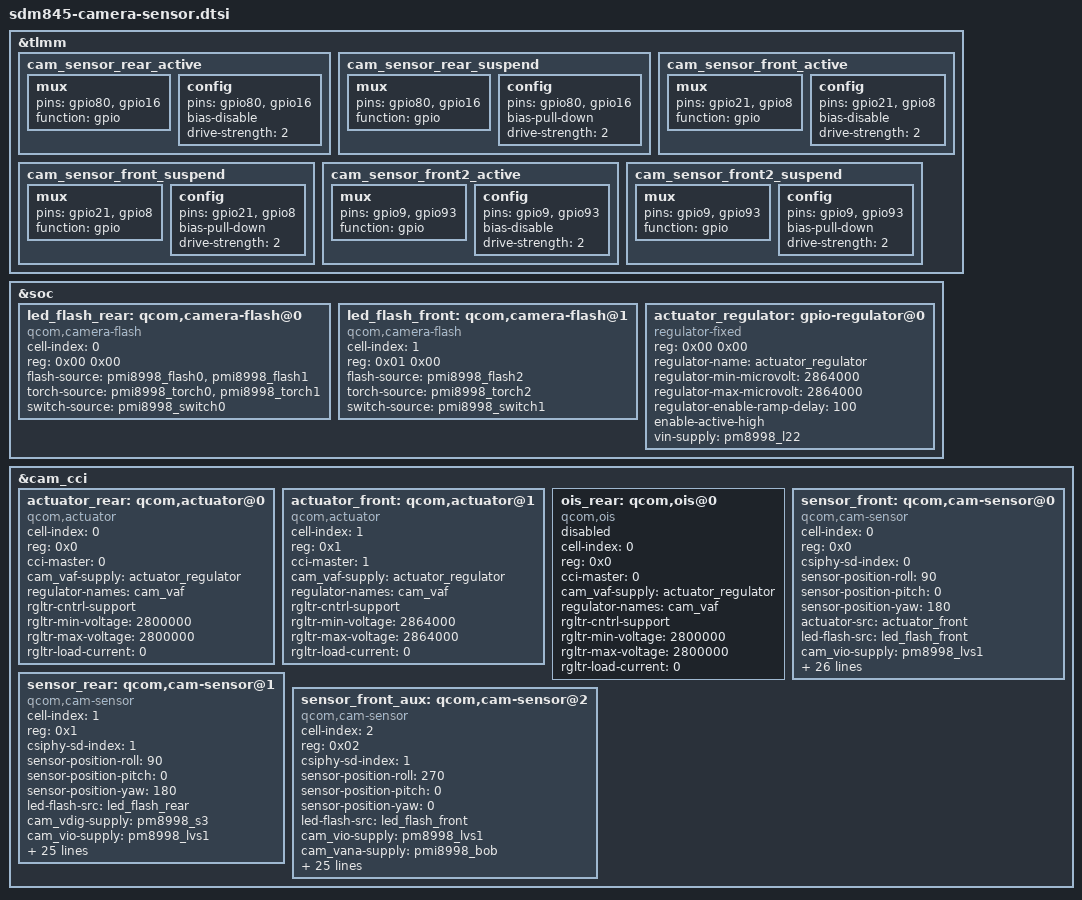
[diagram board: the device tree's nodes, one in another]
/*
 * Copyright (c) 2016-2017, The Linux Foundation. All rights reserved.
 *
 * This program is free software; you can redistribute it and/or modify
 * it under the terms of the GNU General Public License version 2 and
 * only version 2 as published by the Free Software Foundation.
 *
 * This program is distributed in the hope that it will be useful,
 * but WITHOUT ANY WARRANTY; without even the implied warranty of
 * MERCHANTABILITY or FITNESS FOR A PARTICULAR PURPOSE.  See the
 * GNU General Public License for more details.
 */

&tlmm {
	cam_sensor_rear_active: cam_sensor_rear_active {
		/* RESET, AVDD LDO */
		mux {
			pins = "gpio80","gpio16";
			function = "gpio";
		};

		config {
			pins = "gpio80","gpio16";
			bias-disable; /* No PULL */
			drive-strength = <2>; /* 2 MA */
		};
	};

	cam_sensor_rear_suspend: cam_sensor_rear_suspend {
		/* RESET, AVDD LDO */
		mux {
			pins = "gpio80","gpio16";
			function = "gpio";
		};

		config {
			pins = "gpio80","gpio16";
			bias-pull-down; /* PULL DOWN */
			drive-strength = <2>; /* 2 MA */
		};
	};

	cam_sensor_front_active: cam_sensor_front_active {
		/* RESET  AVDD_LDO*/
		mux {
			pins = "gpio21", "gpio8";
			function = "gpio";
		};

		config {
			pins = "gpio21", "gpio8";
			bias-disable; /* No PULL */
			drive-strength = <2>; /* 2 MA */
		};
	};

	cam_sensor_front_suspend: cam_sensor_front_suspend {
		/* RESET  AVDD_LDO*/
		mux {
			pins = "gpio21", "gpio8";
			function = "gpio";
		};

		config {
			pins = "gpio21", "gpio8";
			bias-pull-down; /* PULL DOWN */
			drive-strength = <2>; /* 2 MA */
		};
	};

	cam_sensor_front2_active: cam_sensor_front2_active {
		/* RESET  AVDD_LDO*/
		mux {
			pins = "gpio9", "gpio93";
			function = "gpio";
		};

		config {
			pins = "gpio9", "gpio93";
			bias-disable; /* No PULL */
			drive-strength = <2>; /* 2 MA */
		};
	};

	cam_sensor_front2_suspend: cam_sensor_front2_suspend {
		/* RESET  AVDD_LDO*/
		mux {
			pins = "gpio9", "gpio93";
			function = "gpio";
		};

		config {
			pins = "gpio9", "gpio93";
			bias-pull-down; /* PULL DOWN */
			drive-strength = <2>; /* 2 MA */
		};
	};
};

&soc {
	led_flash_rear: qcom,camera-flash@0 {
		cell-index = <0>;
		reg = <0x00 0x00>;
		compatible = "qcom,camera-flash";
		flash-source = <&pmi8998_flash0 &pmi8998_flash1>;
		torch-source = <&pmi8998_torch0 &pmi8998_torch1>;
		switch-source = <&pmi8998_switch0>;
		status = "ok";
	};

	led_flash_front: qcom,camera-flash@1 {
		cell-index = <1>;
		reg = <0x01 0x00>;
		compatible = "qcom,camera-flash";
		flash-source = <&pmi8998_flash2>;
		torch-source = <&pmi8998_torch2>;
		switch-source = <&pmi8998_switch1>;
		status = "ok";
	};

	actuator_regulator: gpio-regulator@0 {
		compatible = "regulator-fixed";
		reg = <0x00 0x00>;
		regulator-name = "actuator_regulator";
		regulator-min-microvolt = <2864000>;
		regulator-max-microvolt = <2864000>;
		regulator-enable-ramp-delay = <100>;
		enable-active-high;
		vin-supply = <&pm8998_l22>;
	};
};

&cam_cci {
	actuator_rear: qcom,actuator@0 {
		cell-index = <0>;
		reg = <0x0>;
		compatible = "qcom,actuator";
		cci-master = <0>;
		cam_vaf-supply = <&actuator_regulator>;
		regulator-names = "cam_vaf";
		rgltr-cntrl-support;
		rgltr-min-voltage = <2800000>;
		rgltr-max-voltage = <2800000>;
		rgltr-load-current = <0>;
	};

	actuator_front: qcom,actuator@1 {
		cell-index = <1>;
		reg = <0x1>;
		compatible = "qcom,actuator";
		cci-master = <1>;
		cam_vaf-supply = <&actuator_regulator>;
		regulator-names = "cam_vaf";
		rgltr-cntrl-support;
		rgltr-min-voltage = <2864000>;
		rgltr-max-voltage = <2864000>;
		rgltr-load-current = <0>;
	};

	ois_rear: qcom,ois@0 {
		cell-index = <0>;
		reg = <0x0>;
		compatible = "qcom,ois";
		cci-master = <0>;
		cam_vaf-supply = <&actuator_regulator>;
		regulator-names = "cam_vaf";
		rgltr-cntrl-support;
		rgltr-min-voltage = <2800000>;
		rgltr-max-voltage = <2800000>;
		rgltr-load-current = <0>;
		status = "disabled";
	};

	sensor_front: qcom,cam-sensor@0 {
		cell-index = <0>;
		compatible = "qcom,cam-sensor";
		reg = <0x0>;
		csiphy-sd-index = <0>;
		sensor-position-roll = <90>;
		sensor-position-pitch = <0>;
		sensor-position-yaw = <180>;
		actuator-src = <&actuator_front>;
		led-flash-src = <&led_flash_front>;
		cam_vio-supply = <&pm8998_lvs1>;
		cam_vana-supply = <&pmi8998_bob>;
		cam_vdig-supply = <&pm8998_s3>;
		cam_clk-supply = <&titan_top_gdsc>;
		regulator-names = "cam_vio", "cam_vana", "cam_vdig",
			"cam_clk";
		rgltr-cntrl-support;
		rgltr-min-voltage = <0 3312000 1352000 0>;
		rgltr-max-voltage = <0 3600000 1352000 0>;
		rgltr-load-current = <0 80000 105000 0>;
		gpio-no-mux = <0>;
		pinctrl-names = "cam_default", "cam_suspend";
		pinctrl-0 = <&cam_sensor_mclk1_active
				&cam_sensor_front_active>;
		pinctrl-1 = <&cam_sensor_mclk1_suspend
				&cam_sensor_front_suspend>;
		gpios = <&tlmm 14 0>,
			<&tlmm 21 0>,
			<&tlmm 8 0>;
		gpio-reset = <1>;
		gpio-vana = <2>;
		gpio-req-tbl-num = <0 1 2>;
		gpio-req-tbl-flags = <1 0 0>;
		gpio-req-tbl-label = "CAMIF_MCLK1",
					"CAM_RESET1",
					"CAM_VANA1";
		sensor-mode = <0>;
		cci-master = <1>;
		status = "ok";
		clocks = <&clock_camcc CAM_CC_MCLK1_CLK>;
		clock-names = "cam_clk";
		clock-cntl-level = "turbo";
		clock-rates = <24000000>;
	};

	sensor_rear: qcom,cam-sensor@1 {
		cell-index = <1>;
		compatible = "qcom,cam-sensor";
		reg = <0x1>;
		csiphy-sd-index = <1>;
		sensor-position-roll = <90>;
		sensor-position-pitch = <0>;
		sensor-position-yaw = <180>;
		led-flash-src = <&led_flash_rear>;
		cam_vdig-supply = <&pm8998_s3>;
		cam_vio-supply = <&pm8998_lvs1>;
		cam_vana-supply = <&pmi8998_bob>;
		cam_clk-supply = <&titan_top_gdsc>;
		regulator-names = "cam_vdig", "cam_vio", "cam_vana",
			"cam_clk";
		rgltr-cntrl-support;
		rgltr-min-voltage = <1352000 0 3312000 0>;
		rgltr-max-voltage = <1352000 0 3600000 0>;
		rgltr-load-current = <105000 0 80000 0>;
		gpio-no-mux = <0>;
		pinctrl-names = "cam_default", "cam_suspend";
		pinctrl-0 = <&cam_sensor_mclk0_active
				&cam_sensor_rear_active>;
		pinctrl-1 = <&cam_sensor_mclk0_suspend
				&cam_sensor_rear_suspend>;
		gpios = <&tlmm 13 0>,
			<&tlmm 80 0>,
			<&tlmm 16 0>;
		gpio-reset = <1>;
		gpio-vana = <2>;
		gpio-req-tbl-num = <0 1 2>;
		gpio-req-tbl-flags = <1 0 0>;
		gpio-req-tbl-label = "CAMIF_MCLK0",
					"CAM_RESET0",
					"CAM_VANA0";
		sensor-mode = <0>;
		cci-master = <0>;
		status = "ok";
		clocks = <&clock_camcc CAM_CC_MCLK0_CLK>;
		clock-names = "cam_clk";
		clock-cntl-level = "turbo";
		clock-rates = <24000000>;
	};

	sensor_front_aux: qcom,cam-sensor@2 {
		cell-index = <2>;
		compatible = "qcom,cam-sensor";
		reg = <0x02>;
		csiphy-sd-index = <1>;
		sensor-position-roll = <270>;
		sensor-position-pitch = <0>;
		sensor-position-yaw = <0>;
		//eeprom-src = <&eeprom_front>;
		led-flash-src = <&led_flash_front>;
		cam_vio-supply = <&pm8998_lvs1>;
		cam_vana-supply = <&pmi8998_bob>;
		cam_vdig-supply = <&pm8998_s3>;
		cam_clk-supply = <&titan_top_gdsc>;
		regulator-names = "cam_vio", "cam_vana", "cam_vdig",
			"cam_clk";
		rgltr-cntrl-support;
		rgltr-min-voltage = <0 3312000 1352000 0>;
		rgltr-max-voltage = <0 3600000 1352000 0>;
		rgltr-load-current = <0 80000 105000 0>;
		gpio-no-mux = <0>;
		pinctrl-names = "cam_default", "cam_suspend";
		pinctrl-0 = <&cam_sensor_mclk2_active
				 &cam_sensor_front2_active>;
		pinctrl-1 = <&cam_sensor_mclk2_suspend
				 &cam_sensor_front2_suspend>;
		gpios = <&tlmm 15 0>,
			<&tlmm 9 0>,
			<&tlmm 93 0>;
		gpio-reset = <1>;
		gpio-vana = <2>;
		gpio-req-tbl-num = <0 1 2>;
		gpio-req-tbl-flags = <1 0 0>;
		gpio-req-tbl-label = "CAMIF_MCLK2",
					"CAM_RESET2",
					"CAM_VANA2";
		sensor-mode = <0>;
		cci-master = <1>;
		status = "ok";
		clocks = <&clock_camcc CAM_CC_MCLK2_CLK>;
		clock-names = "cam_clk";
		clock-cntl-level = "turbo";
		clock-rates = <24000000>;
	};
};
